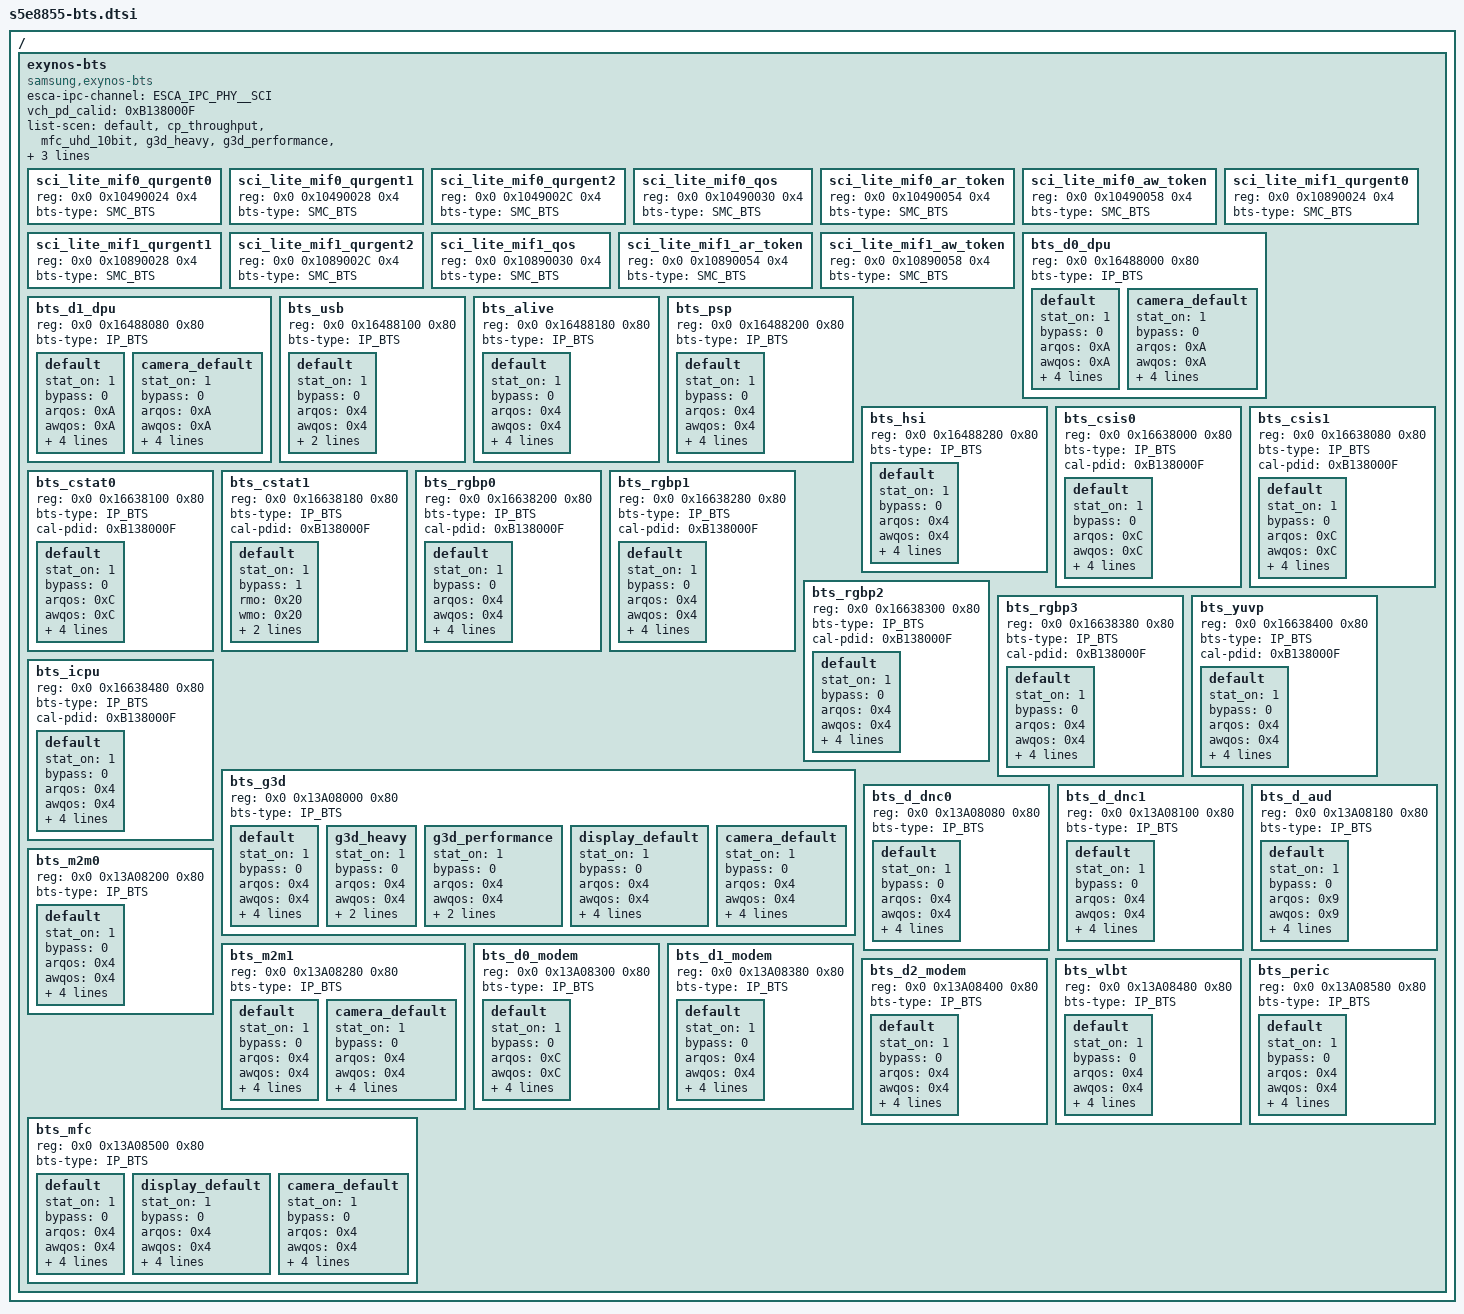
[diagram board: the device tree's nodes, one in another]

/*
 * SAMSUNG EXYNOS SoC BTS device tree source
 *
 * Copyright (c) 2018 Samsung Electronics Co., Ltd.
 *		http://www.samsung.com
 *
 * SAMSUNG EXYNOS SoC BTS device nodes are listed in this file.
 * EXYNOS based board files should include this file.
 *
 * This program is free software; you can redistribute it and/or modify
 * it under the terms of the GNU General Public License version 2 as
 * published by the Free Software Foundation.
 *
 */

#include <dt-bindings/soc/samsung/exynos-bts.h>
#include <dt-bindings/soc/samsung/s5e8855-esca-ipc.h>
/*
TREX_D_NOCL0	0x13A0_0000
TREX_D_NOCL1A 	0x1648_0000
TREX_D_NOCL1B	0x1663_0000
*/

/ {
	exynos-bts {
		compatible = "samsung,exynos-bts";
		#address-cells = <2>;
		#size-cells = <1>;
		ranges;
		esca-ipc-channel = <ESCA_IPC_PHY__SCI>;
		vch_pd_calid = <0xB138000F>;

		list-scen = "default",
			"cp_throughput",
			"mfc_uhd_10bit",
			"g3d_heavy",
			"g3d_performance",
			"display_default",
			"camera_default",
			"npu_normal",
			"npu_performance";

	        /* num_channel, mif_bus_width, bus_width, mif_util, int_util*/
	        bw_params = <2 8 16 65 70>;

		/* SCI_LITE */
		sci_lite_mif0_qurgent0 {
			reg = <0x0 0x10490024 0x4>;
			status = "okay";
			bts-type = <SMC_BTS>;
		};

		sci_lite_mif0_qurgent1 {
			reg = <0x0 0x10490028 0x4>;
			status = "okay";
			bts-type = <SMC_BTS>;
		};

		sci_lite_mif0_qurgent2 {
			reg = <0x0 0x1049002C 0x4>;
			status = "okay";
			bts-type = <SMC_BTS>;
		};

		sci_lite_mif0_qos {
			reg = <0x0 0x10490030 0x4>;
			status = "okay";
			bts-type = <SMC_BTS>;
		};

		sci_lite_mif0_ar_token {
			reg = <0x0 0x10490054 0x4>;
			status = "okay";
			bts-type = <SMC_BTS>;
		};

		sci_lite_mif0_aw_token {
			reg = <0x0 0x10490058 0x4>;
			status = "okay";
			bts-type = <SMC_BTS>;
		};

		sci_lite_mif1_qurgent0 {
			reg = <0x0 0x10890024 0x4>;
			status = "okay";
			bts-type = <SMC_BTS>;
		};

		sci_lite_mif1_qurgent1 {
			reg = <0x0 0x10890028 0x4>;
			status = "okay";
			bts-type = <SMC_BTS>;
		};

		sci_lite_mif1_qurgent2 {
			reg = <0x0 0x1089002C 0x4>;
			status = "okay";
			bts-type = <SMC_BTS>;
		};

		sci_lite_mif1_qos {
			reg = <0x0 0x10890030 0x4>;
			status = "okay";
			bts-type = <SMC_BTS>;
		};

		sci_lite_mif1_ar_token {
			reg = <0x0 0x10890054 0x4>;
			status = "okay";
			bts-type = <SMC_BTS>;
		};

		sci_lite_mif1_aw_token {
			reg = <0x0 0x10890058 0x4>;
			status = "okay";
			bts-type = <SMC_BTS>;
		};

		/* TREX_D_NOCL1A */
		bts_d0_dpu {
			reg = <0x0 0x16488000 0x80>;
			status = "okay";
			bts-type = <IP_BTS>;
			default {
				stat_on = <1>;
				bypass = <0>;
				arqos = <0xA>;
				awqos = <0xA>;
				qurgent_on = <1>;
				qurgent_th_r = <0x14>;
				qurgent_th_w = <0x14>;
				blocking_on = <0>;
			};
			camera_default {
				stat_on = <1>;
				bypass = <0>;
				arqos = <0xA>;
				awqos = <0xA>;
				qurgent_on = <1>;
				qurgent_th_r = <0x30>;
				qurgent_th_w = <0x30>;
				blocking_on = <0>;
			};
		};

		bts_d1_dpu {
			reg = <0x0 0x16488080 0x80>;
			status = "okay";
			bts-type = <IP_BTS>;
			default {
				stat_on = <1>;
				bypass = <0>;
				arqos = <0xA>;
				awqos = <0xA>;
				qurgent_on = <1>;
				qurgent_th_r = <0x14>;
				qurgent_th_w = <0x14>;
				blocking_on = <0>;
			};
			camera_default {
				stat_on = <1>;
				bypass = <0>;
				arqos = <0xA>;
				awqos = <0xA>;
				qurgent_on = <1>;
				qurgent_th_r = <0x30>;
				qurgent_th_w = <0x30>;
				blocking_on = <0>;
			};
		};

		bts_usb {
			reg = <0x0 0x16488100 0x80>;
			status = "okay";
			bts-type = <IP_BTS>;
			default {
				stat_on = <1>;
				bypass = <0>;
				arqos = <0x4>;
				awqos = <0x4>;
				qurgent_on = <0>;
				blocking_on = <0>;
			};
		};

		bts_alive {
			reg = <0x0 0x16488180 0x80>;
			status = "okay";
			bts-type = <IP_BTS>;
			default {
				stat_on = <1>;
				bypass = <0>;
				arqos = <0x4>;
				awqos = <0x4>;
				rmo = <0x4>;
				wmo = <0x4>;
				qurgent_on = <0>;
				blocking_on = <0>;
			};
		};

		bts_psp {
			reg = <0x0 0x16488200 0x80>;
			status = "okay";
			bts-type = <IP_BTS>;
			default {
				stat_on = <1>;
				bypass = <0>;
				arqos = <0x4>;
				awqos = <0x4>;
				rmo = <0x4>;
				wmo = <0x4>;
				qurgent_on = <0>;
				blocking_on = <0>;
			};
		};

		bts_hsi {
			reg = <0x0 0x16488280 0x80>;
			status = "okay";
			bts-type = <IP_BTS>;
			default {
				stat_on = <1>;
				bypass = <0>;
				arqos = <0x4>;
				awqos = <0x4>;
				rmo = <0x4>;
				wmo = <0x4>;
				qurgent_on = <0>;
				blocking_on = <0>;
			};
		};

		/* TREX_D_NOCL1B */
		bts_csis0 {
			reg = <0x0 0x16638000 0x80>;
			status = "okay";
			bts-type = <IP_BTS>;
			cal-pdid = <0xB138000F>;
			default {
				stat_on = <1>;
				bypass = <0>;
				arqos = <0xC>;
				awqos = <0xC>;
				qurgent_on = <1>;
				qurgent_th_r = <0x14>;
				qurgent_th_w = <0xD>;
				blocking_on = <0>;
			};
		};

		bts_csis1 {
			reg = <0x0 0x16638080 0x80>;
			status = "okay";
			bts-type = <IP_BTS>;
			cal-pdid = <0xB138000F>;
			default {
				stat_on = <1>;
				bypass = <0>;
				arqos = <0xC>;
				awqos = <0xC>;
				qurgent_on = <1>;
				qurgent_th_r = <0x14>;
				qurgent_th_w = <0xD>;
				blocking_on = <0>;
			};
		};

		bts_cstat0 {
			reg = <0x0 0x16638100 0x80>;
			status = "okay";
			bts-type = <IP_BTS>;
			cal-pdid = <0xB138000F>;
			default {
				stat_on = <1>;
				bypass = <0>;
				arqos = <0xC>;
				awqos = <0xC>;
				qurgent_on = <1>;
				qurgent_th_r = <0x14>;
				qurgent_th_w = <0xD>;
				blocking_on = <0>;
			};
		};

		bts_cstat1 {
			reg = <0x0 0x16638180 0x80>;
			status = "okay";
			bts-type = <IP_BTS>;
			cal-pdid = <0xB138000F>;
			default {
				stat_on = <1>;
				bypass = <1>;
				rmo = <0x20>;
				wmo = <0x20>;
				qurgent_on = <0>;
				blocking_on = <0>;
			};
		};

		bts_rgbp0 {
			reg = <0x0 0x16638200 0x80>;
			status = "okay";
			bts-type = <IP_BTS>;
			cal-pdid = <0xB138000F>;
			default {
				stat_on = <1>;
				bypass = <0>;
				arqos = <0x4>;
				awqos = <0x4>;
				rmo = <0x20>;
				wmo = <0x20>;
				qurgent_on = <0>;
				blocking_on = <0>;
			};
		};

		bts_rgbp1 {
			reg = <0x0 0x16638280 0x80>;
			status = "okay";
			bts-type = <IP_BTS>;
			cal-pdid = <0xB138000F>;
			default {
				stat_on = <1>;
				bypass = <0>;
				arqos = <0x4>;
				awqos = <0x4>;
				rmo = <0x20>;
				wmo = <0x20>;
				qurgent_on = <0>;
				blocking_on = <0>;
			};
		};

		bts_rgbp2 {
			reg = <0x0 0x16638300 0x80>;
			status = "okay";
			bts-type = <IP_BTS>;
			cal-pdid = <0xB138000F>;
			default {
				stat_on = <1>;
				bypass = <0>;
				arqos = <0x4>;
				awqos = <0x4>;
				rmo = <0x20>;
				wmo = <0x20>;
				qurgent_on = <0>;
				blocking_on = <0>;
			};
		};

		bts_rgbp3 {
			reg = <0x0 0x16638380 0x80>;
			status = "okay";
			bts-type = <IP_BTS>;
			cal-pdid = <0xB138000F>;
			default {
				stat_on = <1>;
				bypass = <0>;
				arqos = <0x4>;
				awqos = <0x4>;
				rmo = <0x20>;
				wmo = <0x20>;
				qurgent_on = <0>;
				blocking_on = <0>;
			};
		};

		bts_yuvp {
			reg = <0x0 0x16638400 0x80>;
			status = "okay";
			bts-type = <IP_BTS>;
			cal-pdid = <0xB138000F>;
			default {
				stat_on = <1>;
				bypass = <0>;
				arqos = <0x4>;
				awqos = <0x4>;
				rmo = <0x20>;
				wmo = <0x20>;
				qurgent_on = <0>;
				blocking_on = <0>;
			};
		};

		bts_icpu {
			reg = <0x0 0x16638480 0x80>;
			status = "okay";
			bts-type = <IP_BTS>;
			cal-pdid = <0xB138000F>;
			default {
				stat_on = <1>;
				bypass = <0>;
				arqos = <0x4>;
				awqos = <0x4>;
				rmo = <0x20>;
				wmo = <0x20>;
				qurgent_on = <0>;
				blocking_on = <0>;
			};
		};

		/* TREX_D_NOCL0 */
		bts_g3d {
			reg = <0x0 0x13A08000 0x80>;
			status = "okay";
			bts-type = <IP_BTS>;
			default {
				stat_on = <1>;
				bypass = <0>;
				arqos = <0x4>;
				awqos = <0x4>;
				rmo = <0x8>;
				wmo = <0x4>;
				qurgent_on = <0>;
				blocking_on = <0>;
			};
			g3d_heavy {
				stat_on = <1>;
				bypass = <0>;
				arqos = <0x4>;
				awqos = <0x4>;
				rmo = <0x40>;
				wmo = <0x40>;
			};
			g3d_performance {
				stat_on = <1>;
				bypass = <0>;
				arqos = <0x4>;
				awqos = <0x4>;
				rmo = <0x40>;
				wmo = <0x40>;
			};
			display_default {
				stat_on = <1>;
				bypass = <0>;
				arqos = <0x4>;
				awqos = <0x4>;
				rmo = <0x40>;
				wmo = <0x40>;
				qurgent_on = <0>;
				blocking_on = <0>;
			};
			camera_default {
				stat_on = <1>;
				bypass = <0>;
				arqos = <0x4>;
				awqos = <0x4>;
				rmo = <0x8>;
				wmo = <0x8>;
				qurgent_on = <0>;
				blocking_on = <0>;
			};
		};

		bts_d_dnc0 {
			reg = <0x0 0x13A08080 0x80>;
			status = "okay";
			bts-type = <IP_BTS>;
			default {
				stat_on = <1>;
				bypass = <0>;
				arqos = <0x4>;
				awqos = <0x4>;
				rmo = <0x30>;
				wmo = <0x30>;
				qurgent_on = <0>;
				blocking_on = <0>;
			};
		};

		bts_d_dnc1 {
			reg = <0x0 0x13A08100 0x80>;
			status = "okay";
			bts-type = <IP_BTS>;
			default {
				stat_on = <1>;
				bypass = <0>;
				arqos = <0x4>;
				awqos = <0x4>;
				rmo = <0x30>;
				wmo = <0x30>;
				qurgent_on = <0>;
				blocking_on = <0>;
			};
		};

		bts_d_aud {
			reg = <0x0 0x13A08180 0x80>;
			status = "okay";
			bts-type = <IP_BTS>;
			default {
				stat_on = <1>;
				bypass = <0>;
				arqos = <0x9>;
				awqos = <0x9>;
				qurgent_on = <1>;
				qurgent_th_r = <0x14>;
				qurgent_th_w = <0x14>;
				blocking_on = <0>;
			};
		};

		bts_m2m0 {
			reg = <0x0 0x13A08200 0x80>;
			status = "okay";
			bts-type = <IP_BTS>;
			default {
				stat_on = <1>;
				bypass = <0>;
				arqos = <0x4>;
				awqos = <0x4>;
				rmo = <0x8>;
				wmo = <0x8>;
				qurgent_on = <0>;
				blocking_on = <0>;
			};
		};

		bts_m2m1 {
			reg = <0x0 0x13A08280 0x80>;
			status = "okay";
			bts-type = <IP_BTS>;
			default {
				stat_on = <1>;
				bypass = <0>;
				arqos = <0x4>;
				awqos = <0x4>;
				rmo = <0x10>;
				wmo = <0x10>;
				qurgent_on = <0>;
				blocking_on = <0>;
			};
			camera_default {
				stat_on = <1>;
				bypass = <0>;
				arqos = <0x4>;
				awqos = <0x4>;
				rmo = <0xA>;
				wmo = <0xA>;
				qurgent_on = <0>;
				blocking_on = <0>;
			};
		};

		bts_d0_modem {
			reg = <0x0 0x13A08300 0x80>;
			status = "okay";
			bts-type = <IP_BTS>;
			default {
				stat_on = <1>;
				bypass = <0>;
				arqos = <0xC>;
				awqos = <0xC>;
				qurgent_on = <1>;
				qurgent_th_r = <0x14>;
				qurgent_th_w = <0x14>;
				blocking_on = <0>;
			};
		};

		bts_d1_modem {
			reg = <0x0 0x13A08380 0x80>;
			status = "okay";
			bts-type = <IP_BTS>;
			default {
				stat_on = <1>;
				bypass = <0>;
				arqos = <0x4>;
				awqos = <0x4>;
				rmo = <0x14>;
				wmo = <0x14>;
				qurgent_on = <0>;
				blocking_on = <0>;
			};
		};

		bts_d2_modem {
			reg = <0x0 0x13A08400 0x80>;
			status = "okay";
			bts-type = <IP_BTS>;
			default {
				stat_on = <1>;
				bypass = <0>;
				arqos = <0x4>;
				awqos = <0x4>;
				rmo = <0x14>;
				wmo = <0x14>;
				qurgent_on = <0>;
				blocking_on = <0>;
			};
		};

		bts_wlbt {
			reg = <0x0 0x13A08480 0x80>;
			status = "okay";
			bts-type = <IP_BTS>;
			default {
				stat_on = <1>;
				bypass = <0>;
				arqos = <0x4>;
				awqos = <0x4>;
				rmo = <0x4>;
				wmo = <0x4>;
				qurgent_on = <0>;
				blocking_on = <0>;
			};
		};

		bts_mfc {
			reg = <0x0 0x13A08500 0x80>;
			status = "okay";
			bts-type = <IP_BTS>;
			default {
				stat_on = <1>;
				bypass = <0>;
				arqos = <0x4>;
				awqos = <0x4>;
				rmo = <0x10>;
				wmo = <0x10>;
				qurgent_on = <0>;
				blocking_on = <0>;
			};
			display_default {
				stat_on = <1>;
				bypass = <0>;
				arqos = <0x4>;
				awqos = <0x4>;
				rmo = <0x40>;
				wmo = <0x20>;
				qurgent_on = <0>;
				blocking_on = <0>;
			};
			camera_default {
				stat_on = <1>;
				bypass = <0>;
				arqos = <0x4>;
				awqos = <0x4>;
				rmo = <0xF>;
				wmo = <0xF>;
				qurgent_on = <0>;
				blocking_on = <0>;
			};
		};

		bts_peric {
			reg = <0x0 0x13A08580 0x80>;
			status = "okay";
			bts-type = <IP_BTS>;
			default {
				stat_on = <1>;
				bypass = <0>;
				arqos = <0x4>;
				awqos = <0x4>;
				rmo = <0x4>;
				wmo = <0x4>;
				qurgent_on = <0>;
				blocking_on = <0>;
			};
		};
	};
};
